# MSS_CTRL_MSS_CTRL_50D00000h register map
Vendor: Texas Instruments
Registers are 32-bit, read-only, reset values left out (the file's numbers can be read two ways) unless marked. A register's access mark holds for its fields unless they carry their own. Offsets are as the file gives them; [hi:lo] are bit positions.

## MSS_CTRL (part 7 of 10)
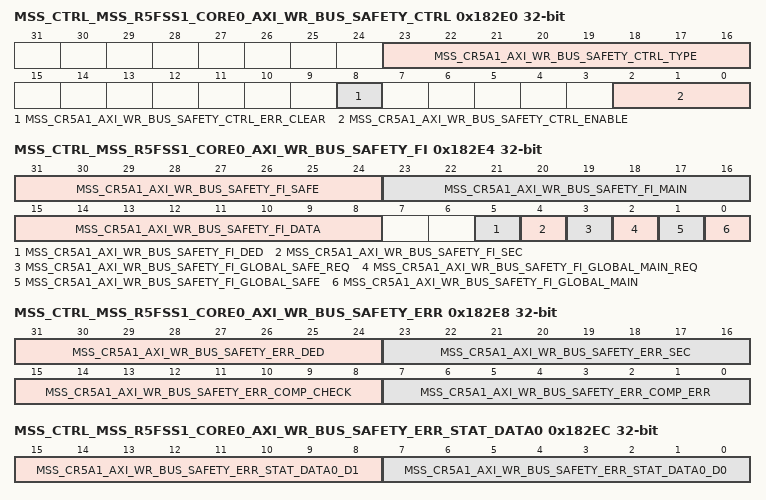
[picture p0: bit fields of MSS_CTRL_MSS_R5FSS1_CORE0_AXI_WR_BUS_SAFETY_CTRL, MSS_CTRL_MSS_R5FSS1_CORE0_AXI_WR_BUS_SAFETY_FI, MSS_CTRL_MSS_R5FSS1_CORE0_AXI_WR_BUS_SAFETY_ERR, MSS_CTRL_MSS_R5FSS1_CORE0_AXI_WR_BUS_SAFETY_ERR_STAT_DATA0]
0x182E0 MSS_CTRL_MSS_R5FSS1_CORE0_AXI_WR_BUS_SAFETY_CTRL access per field — This register is used to Control and Configure the Interconnect Safety Behaviour of R5SS1 CORE0 AXI WR Initiator Port.
  [23:16] MSS_CR5A1_AXI_WR_BUS_SAFETY_CTRL_TYPE ro — This bitfield gives a top level idea of the available bus [cmd,wr,ws,rd] for the particular Target/Initiator and whether it follows the VBUS protocol or not. Bit 0 - 1'b1 indicates the Command bus is implemented to this target/initiator else it is set to 1'b0. Bit 1 - 1'b1 indicates the write bus is implemented to this target/initiator else it is set to 1'b0. Bit 2 - 1'b1 indicates the write status bus is implemented to this target/initiator else it is set to 1'b0. Bit 3 - 1'b1 indicates the read bus is implemented to this target/initiator else it is set to 1'b0. Bit 4 - 1'b0 indicates the port follows the VBUS protocol else it is set to 1'b1. Bits 5-7 are set to 3'b000.
  [8] MSS_CR5A1_AXI_WR_BUS_SAFETY_CTRL_ERR_CLEAR rw — Set this bit to 1'b1 to clear the error status for this port
  [2:0] MSS_CR5A1_AXI_WR_BUS_SAFETY_CTRL_ENABLE rw — Set this bit to 3'b111 to enable the safety configuration for this port. Set this bit to 3'b000 to disable the safety configuration for this port.
0x182E4 MSS_CTRL_MSS_R5FSS1_CORE0_AXI_WR_BUS_SAFETY_FI rw — This register is used to Inject fault on the Interconnect Safety comparator of R5SS1 CORE0 AXI WR Initiator Port.
  [31:24] MSS_CR5A1_AXI_WR_BUS_SAFETY_FI_SAFE — This bitfield is used to inject fault on Read, write, command and request bus on the safe Interconnect. Bit 0 - Set this bit to inject fault on the Command bus. Bit 1 - Set this bit to inject fault on theWrite bus. Bit 2 - Set this bit to inject fault on the Write Status bus.Bit 3 - Set this bit to inject fault on the Read bus. Bit 7- Set this bit to inject fault on the corresponding request bus.
  [23:16] MSS_CR5A1_AXI_WR_BUS_SAFETY_FI_MAIN — This bitfield is used to inject fault on Read, write, command and request bus on the main Interconnect.Bit 0 - Set this bit to inject fault on the Command bus. Bit 1 - Set this bit to inject fault on theWrite bus. Bit 2 - Set this bit to inject fault on the Write Status bus.Bit 3 - Set this bit to inject fault on the Read bus. Bit 7- Set this bit to inject fault on the corresponding request bus.
  [15:8] MSS_CR5A1_AXI_WR_BUS_SAFETY_FI_DATA — Set bit 0 to 1'b1 to inject sec and ded faults on [31:0] bits of data bus.Set bit 1 to 1'b1 to inject sec and ded faults on [64:32] bits of data bus.
  [5] MSS_CR5A1_AXI_WR_BUS_SAFETY_FI_DED — Set this bit to 1'b1 inject ded error on data at this port
  [4] MSS_CR5A1_AXI_WR_BUS_SAFETY_FI_SEC — Set this bit to 1'b1 to inject sec error on data at this port
  [3] MSS_CR5A1_AXI_WR_BUS_SAFETY_FI_GLOBAL_SAFE_REQ — Set this bit 1'b1 to inject fault for request signals on Safe Interconnect. This is enabled only when the 7th bit of safe bitfield of this register and particular bit coressponding to this port on the safe bitfield of this register is set HIGH
  [2] MSS_CR5A1_AXI_WR_BUS_SAFETY_FI_GLOBAL_MAIN_REQ — Set this bit to 1'b1 to inject fault for request signals on main Interconnect. This is enabled only when the 7th bit of main bitfield of this register and particular bit coressponding to this port on the main bitfield of this register is set HIGH
  [1] MSS_CR5A1_AXI_WR_BUS_SAFETY_FI_GLOBAL_SAFE — This is a global safe Fault injection signal. Set this bit to inject fault on all the safety buses of the safe interconnect except req signal. Writing a 1'b1 injects fault on interconnect.
  [0] MSS_CR5A1_AXI_WR_BUS_SAFETY_FI_GLOBAL_MAIN — This is a global main Fault injection signal. Set this bit to inject fault on all the buses of the main interconnect except req signal. Writing a 1'b1 injects fault on interconnect.
0x182E8 MSS_CTRL_MSS_R5FSS1_CORE0_AXI_WR_BUS_SAFETY_ERR — This Register provides the Error Status of Bus Safety Comparator of R5SS1 CORE0 AXI WR Initiator port.
  [31:24] MSS_CR5A1_AXI_WR_BUS_SAFETY_ERR_DED — This flag signals detection of dual error in Data at this port.Flag is generted for 32 bit segment of Data BusBit 0 - 1'b1 indicates ded on [31:0] bit of Data busBit 1 - 1'b1 indicates ded on [63:32] bit of Data busBit [7:2] - Unused. Set to 1'b0
  [23:16] MSS_CR5A1_AXI_WR_BUS_SAFETY_ERR_SEC — This flag signals detection of single error in Data at this port. Flag is generted for 32 bit segment of Data BusBit 0 - 1'b1 indicates sec on [31:0] bit of Data busBit 1 - 1'b1 indicates sec on [63:32] bit of Data busBit [7:2] - Unused. Set to 1'b0
  [15:8] MSS_CR5A1_AXI_WR_BUS_SAFETY_ERR_COMP_CHECK — This is used to verify the proper functioning of fault Injection on all the buses.1'b1 indicates error in the corresponding Bus has been injected successfully. Bit 0 - This is a Bitwise AND of error compares of all command bus signals.Bit 1 - This is a Bitwise AND of error compares of all write bus signals.Bit 2 - This is a Bitwise AND of error compares of all write status bus signals.Bit 3 - This is a Bitwise AND of error compares of all read bus signals.Bits [7:4] are unused.
  [7:0] MSS_CR5A1_AXI_WR_BUS_SAFETY_ERR_COMP_ERR — 1'b1 indicates error in the corresponding Bus whenever a fault is detected at any bus signalBit 0 - This is a Bitwise OR of error compares of all command bus signals.Bit 1 - This is a Bitwise OR of error compares of all write bus signals.Bit 2 - This is a Bitwise OR of error compares of all write status bus signals.Bit 3 - This is a Bitwise OR of error compares of all read bus signals.Bits [7:4] are unused.
0x182EC MSS_CTRL_MSS_R5FSS1_CORE0_AXI_WR_BUS_SAFETY_ERR_STAT_DATA0 — This register Indicates the Error Syndrome of Data errors in Bus Safety Comparator of R5SS1 CORE0 AXI WR Initiator Port.
  [15:8] MSS_CR5A1_AXI_WR_BUS_SAFETY_ERR_STAT_DATA0_D1 — Read this bitfield for Comparator status for Higher 32 bits [63:32] of data bus at this port. It represent the position of the flipped bit in case of SEC.
  [7:0] MSS_CR5A1_AXI_WR_BUS_SAFETY_ERR_STAT_DATA0_D0 — Read this bitfield for Comparator status for lower 32 bits [31:0] of data bus at this port. It represent the position of the flipped bit in case of SEC.
0x182F0 MSS_CTRL_MSS_R5FSS1_CORE0_AXI_WR_BUS_SAFETY_ERR_STAT_CMD — This register Indicates the Error Syndrome of Command errors in Bus Safety Comparator of R5SS1 CORE0 AXI WR Initiator Port.
  [31:0] MSS_CR5A1_AXI_WR_BUS_SAFETY_ERR_STAT_CMD_STAT — Read this bitfield for comparator status for command bus for this port. 1'b1 on any of the bits indicates an error on Command Bus
0x182F4 MSS_CTRL_MSS_R5FSS1_CORE0_AXI_WR_BUS_SAFETY_ERR_STAT_WRITE — This register Indicates the Error Syndrome of Write errors in Bus Safety Comparator of R5SS1 CORE0 AXI WR Initiator Port.
  [31:0] MSS_CR5A1_AXI_WR_BUS_SAFETY_ERR_STAT_WRITE_STAT — Read this bitfield for comparator status for Write bus for this port. 1'b1 at any bit indicates error on Write Bus
0x182F8 MSS_CTRL_MSS_R5FSS1_CORE0_AXI_WR_BUS_SAFETY_ERR_STAT_WRITERESP — This register Indicates the Error Syndrome of Write Response errors in Bus Safety Comparator of R5SS1 CORE0 AXI WR Initiator Port.
  [31:0] MSS_CR5A1_AXI_WR_BUS_SAFETY_ERR_STAT_WRITERESP_STAT — Read this bitfield for comparator status for Write response bus for this port. 1'b1 at any bit indicates error on Write Response Bus.
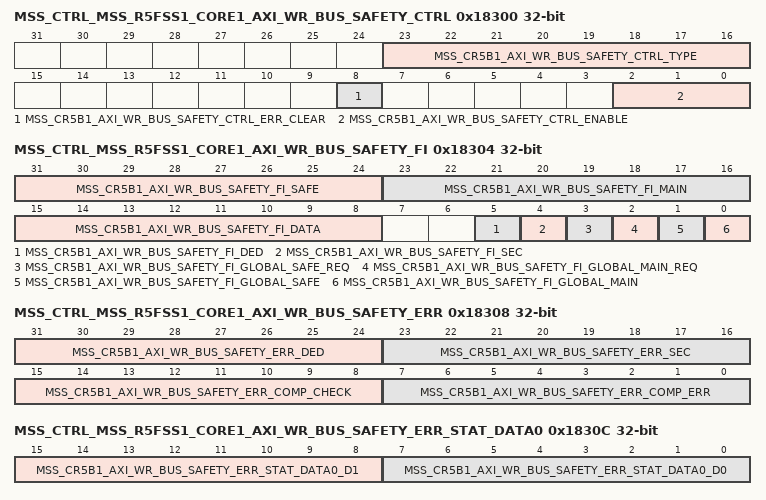
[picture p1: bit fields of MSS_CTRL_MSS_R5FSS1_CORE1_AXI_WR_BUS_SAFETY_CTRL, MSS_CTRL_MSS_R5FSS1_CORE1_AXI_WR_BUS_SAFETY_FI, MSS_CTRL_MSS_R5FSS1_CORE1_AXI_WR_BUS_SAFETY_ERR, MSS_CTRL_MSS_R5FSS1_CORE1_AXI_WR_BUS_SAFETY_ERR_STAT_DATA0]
0x18300 MSS_CTRL_MSS_R5FSS1_CORE1_AXI_WR_BUS_SAFETY_CTRL access per field — This register is used to Control and Configure the Interconnect Safety Behaviour of R5SS1 CORE1 AXI WR Initiator Port.
  [23:16] MSS_CR5B1_AXI_WR_BUS_SAFETY_CTRL_TYPE ro — This bitfield gives a top level idea of the available bus [cmd,wr,ws,rd] for the particular Target/Initiator and whether it follows the VBUS protocol or not. Bit 0 - 1'b1 indicates the Command bus is implemented to this target/initiator else it is set to 1'b0. Bit 1 - 1'b1 indicates the write bus is implemented to this target/initiator else it is set to 1'b0. Bit 2 - 1'b1 indicates the write status bus is implemented to this target/initiator else it is set to 1'b0. Bit 3 - 1'b1 indicates the read bus is implemented to this target/initiator else it is set to 1'b0. Bit 4 - 1'b0 indicates the port follows the VBUS protocol else it is set to 1'b1. Bits 5-7 are set to 3'b000.
  [8] MSS_CR5B1_AXI_WR_BUS_SAFETY_CTRL_ERR_CLEAR rw — Set this bit to 1'b1 to clear the error status for this port
  [2:0] MSS_CR5B1_AXI_WR_BUS_SAFETY_CTRL_ENABLE rw — Set this bit to 3'b111 to enable the safety configuration for this port. Set this bit to 3'b000 to disable the safety configuration for this port.
0x18304 MSS_CTRL_MSS_R5FSS1_CORE1_AXI_WR_BUS_SAFETY_FI rw — This register is used to Inject fault on the Interconnect Safety comparator of R5SS1 CORE1 AXI WR Initiator Port.
  [31:24] MSS_CR5B1_AXI_WR_BUS_SAFETY_FI_SAFE — This bitfield is used to inject fault on Read, write, command and request bus on the safe Interconnect. Bit 0 - Set this bit to inject fault on the Command bus. Bit 1 - Set this bit to inject fault on theWrite bus. Bit 2 - Set this bit to inject fault on the Write Status bus.Bit 3 - Set this bit to inject fault on the Read bus. Bit 7- Set this bit to inject fault on the corresponding request bus.
  [23:16] MSS_CR5B1_AXI_WR_BUS_SAFETY_FI_MAIN — This bitfield is used to inject fault on Read, write, command and request bus on the main Interconnect.Bit 0 - Set this bit to inject fault on the Command bus. Bit 1 - Set this bit to inject fault on theWrite bus. Bit 2 - Set this bit to inject fault on the Write Status bus.Bit 3 - Set this bit to inject fault on the Read bus. Bit 7- Set this bit to inject fault on the corresponding request bus.
  [15:8] MSS_CR5B1_AXI_WR_BUS_SAFETY_FI_DATA — Set bit 0 to 1'b1 to inject sec and ded faults on [31:0] bits of data bus.Set bit 1 to 1'b1 to inject sec and ded faults on [64:32] bits of data bus.
  [5] MSS_CR5B1_AXI_WR_BUS_SAFETY_FI_DED — Set this bit to 1'b1 inject ded error on data at this port
  [4] MSS_CR5B1_AXI_WR_BUS_SAFETY_FI_SEC — Set this bit to 1'b1 to inject sec error on data at this port
  [3] MSS_CR5B1_AXI_WR_BUS_SAFETY_FI_GLOBAL_SAFE_REQ — Set this bit 1'b1 to inject fault for request signals on Safe Interconnect. This is enabled only when the 7th bit of safe bitfield of this register and particular bit coressponding to this port on the safe bitfield of this register is set HIGH
  [2] MSS_CR5B1_AXI_WR_BUS_SAFETY_FI_GLOBAL_MAIN_REQ — Set this bit to 1'b1 to inject fault for request signals on main Interconnect. This is enabled only when the 7th bit of main bitfield of this register and particular bit coressponding to this port on the main bitfield of this register is set HIGH
  [1] MSS_CR5B1_AXI_WR_BUS_SAFETY_FI_GLOBAL_SAFE — This is a global safe Fault injection signal. Set this bit to inject fault on all the safety buses of the safe interconnect except req signal. Writing a 1'b1 injects fault on interconnect.
  [0] MSS_CR5B1_AXI_WR_BUS_SAFETY_FI_GLOBAL_MAIN — This is a global main Fault injection signal. Set this bit to inject fault on all the buses of the main interconnect except req signal. Writing a 1'b1 injects fault on interconnect.
0x18308 MSS_CTRL_MSS_R5FSS1_CORE1_AXI_WR_BUS_SAFETY_ERR — This Register provides the Error Status of Bus Safety Comparator of R5SS1 CORE1 AXI WR Initiator port.
  [31:24] MSS_CR5B1_AXI_WR_BUS_SAFETY_ERR_DED — This flag signals detection of dual error in Data at this port.Flag is generted for 32 bit segment of Data BusBit 0 - 1'b1 indicates ded on [31:0] bit of Data busBit 1 - 1'b1 indicates ded on [63:32] bit of Data busBit [7:2] - Unused. Set to 1'b0
  [23:16] MSS_CR5B1_AXI_WR_BUS_SAFETY_ERR_SEC — This flag signals detection of single error in Data at this port. Flag is generted for 32 bit segment of Data BusBit 0 - 1'b1 indicates sec on [31:0] bit of Data busBit 1 - 1'b1 indicates sec on [63:32] bit of Data busBit [7:2] - Unused. Set to 1'b0
  [15:8] MSS_CR5B1_AXI_WR_BUS_SAFETY_ERR_COMP_CHECK — This is used to verify the proper functioning of fault Injection on all the buses.1'b1 indicates error in the corresponding Bus has been injected successfully. Bit 0 - This is a Bitwise AND of error compares of all command bus signals.Bit 1 - This is a Bitwise AND of error compares of all write bus signals.Bit 2 - This is a Bitwise AND of error compares of all write status bus signals.Bit 3 - This is a Bitwise AND of error compares of all read bus signals.Bits [7:4] are unused.
  [7:0] MSS_CR5B1_AXI_WR_BUS_SAFETY_ERR_COMP_ERR — 1'b1 indicates error in the corresponding Bus whenever a fault is detected at any bus signalBit 0 - This is a Bitwise OR of error compares of all command bus signals.Bit 1 - This is a Bitwise OR of error compares of all write bus signals.Bit 2 - This is a Bitwise OR of error compares of all write status bus signals.Bit 3 - This is a Bitwise OR of error compares of all read bus signals.Bits [7:4] are unused.
0x1830C MSS_CTRL_MSS_R5FSS1_CORE1_AXI_WR_BUS_SAFETY_ERR_STAT_DATA0 — This register Indicates the Error Syndrome of Data errors in Bus Safety Comparator of R5SS1 CORE1 AXI WR Initiator Port.
  [15:8] MSS_CR5B1_AXI_WR_BUS_SAFETY_ERR_STAT_DATA0_D1 — Read this bitfield for Comparator status for Higher 32 bits [63:32] of data bus at this port. It represent the position of the flipped bit in case of SEC.
  [7:0] MSS_CR5B1_AXI_WR_BUS_SAFETY_ERR_STAT_DATA0_D0 — Read this bitfield for Comparator status for lower 32 bits [31:0] of data bus at this port. It represent the position of the flipped bit in case of SEC.
0x18310 MSS_CTRL_MSS_R5FSS1_CORE1_AXI_WR_BUS_SAFETY_ERR_STAT_CMD — This register Indicates the Error Syndrome of Command errors in Bus Safety Comparator of R5SS1 CORE1 AXI WR Initiator Port.
  [31:0] MSS_CR5B1_AXI_WR_BUS_SAFETY_ERR_STAT_CMD_STAT — Read this bitfield for comparator status for command bus for this port. 1'b1 on any of the bits indicates an error on Command Bus
0x18314 MSS_CTRL_MSS_R5FSS1_CORE1_AXI_WR_BUS_SAFETY_ERR_STAT_WRITE — This register Indicates the Error Syndrome of Write errors in Bus Safety Comparator of R5SS1 CORE1 AXI WR Initiator Port.
  [31:0] MSS_CR5B1_AXI_WR_BUS_SAFETY_ERR_STAT_WRITE_STAT — Read this bitfield for comparator status for Write bus for this port. 1'b1 at any bit indicates error on Write Bus
0x18318 MSS_CTRL_MSS_R5FSS1_CORE1_AXI_WR_BUS_SAFETY_ERR_STAT_WRITERESP — This register Indicates the Error Syndrome of Write Response errors in Bus Safety Comparator of R5SS1 CORE1 AXI WR Initiator Port.
  [31:0] MSS_CR5B1_AXI_WR_BUS_SAFETY_ERR_STAT_WRITERESP_STAT — Read this bitfield for comparator status for Write response bus for this port. 1'b1 at any bit indicates error on Write Response Bus.
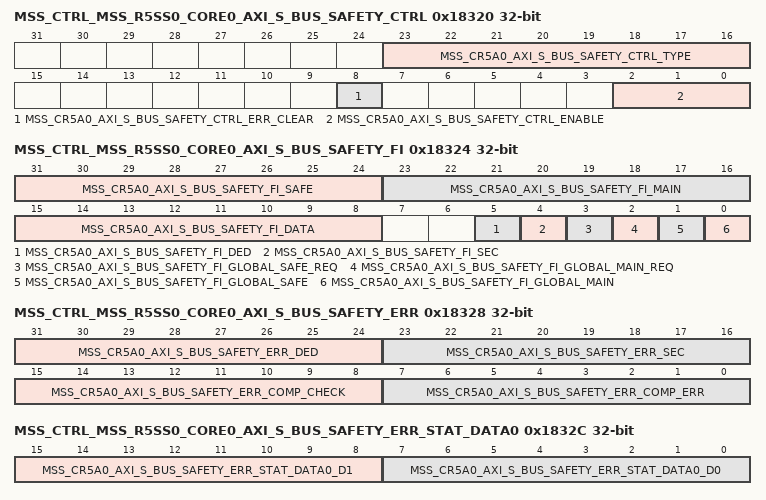
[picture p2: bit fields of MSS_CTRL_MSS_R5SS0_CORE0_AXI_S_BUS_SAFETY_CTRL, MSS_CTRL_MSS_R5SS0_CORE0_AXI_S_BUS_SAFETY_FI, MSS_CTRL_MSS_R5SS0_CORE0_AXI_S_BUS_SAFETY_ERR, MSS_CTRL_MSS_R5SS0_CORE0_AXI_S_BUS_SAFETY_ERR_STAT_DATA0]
0x18320 MSS_CTRL_MSS_R5SS0_CORE0_AXI_S_BUS_SAFETY_CTRL access per field — This register is used to Control and Configure the Interconnect Safety Behaviour of R5SS0 CORE0 AXI Target Port.
  [23:16] MSS_CR5A0_AXI_S_BUS_SAFETY_CTRL_TYPE ro — This bitfield gives a top level idea of the available bus [cmd,wr,ws,rd] for the particular Target/Initiator and whether it follows the VBUS protocol or not. Bit 0 - 1'b1 indicates the Command bus is implemented to this target/initiator else it is set to 1'b0. Bit 1 - 1'b1 indicates the write bus is implemented to this target/initiator else it is set to 1'b0. Bit 2 - 1'b1 indicates the write status bus is implemented to this target/initiator else it is set to 1'b0. Bit 3 - 1'b1 indicates the read bus is implemented to this target/initiator else it is set to 1'b0. Bit 4 - 1'b0 indicates the port follows the VBUS protocol else it is set to 1'b1. Bits 5-7 are set to 3'b000.
  [8] MSS_CR5A0_AXI_S_BUS_SAFETY_CTRL_ERR_CLEAR rw — Set this bit to 1'b1 to clear the error status for this port
  [2:0] MSS_CR5A0_AXI_S_BUS_SAFETY_CTRL_ENABLE rw — Set this bit to 3'b111 to enable the safety configuration for this port. Set this bit to 3'b000 to disable the safety configuration for this port.
0x18324 MSS_CTRL_MSS_R5SS0_CORE0_AXI_S_BUS_SAFETY_FI rw — This register is used to Inject fault on the Interconnect Safety comparator of R5SS0 CORE0 AXI Target Port.
  [31:24] MSS_CR5A0_AXI_S_BUS_SAFETY_FI_SAFE — This bitfield is used to inject fault on Read, write, command and request bus on the safe Interconnect. Bit 0 - Set this bit to inject fault on the Command bus. Bit 1 - Set this bit to inject fault on theWrite bus. Bit 2 - Set this bit to inject fault on the Write Status bus.Bit 3 - Set this bit to inject fault on the Read bus. Bit 7- Set this bit to inject fault on the corresponding request bus.
  [23:16] MSS_CR5A0_AXI_S_BUS_SAFETY_FI_MAIN — This bitfield is used to inject fault on Read, write, command and request bus on the main Interconnect.Bit 0 - Set this bit to inject fault on the Command bus. Bit 1 - Set this bit to inject fault on theWrite bus. Bit 2 - Set this bit to inject fault on the Write Status bus.Bit 3 - Set this bit to inject fault on the Read bus. Bit 7- Set this bit to inject fault on the corresponding request bus.
  [15:8] MSS_CR5A0_AXI_S_BUS_SAFETY_FI_DATA — Set bit 0 to 1'b1 to inject sec and ded faults on [31:0] bits of data bus.Set bit 1 to 1'b1 to inject sec and ded faults on [64:32] bits of data bus.
  [5] MSS_CR5A0_AXI_S_BUS_SAFETY_FI_DED — Set this bit to 1'b1 inject ded error on data at this port
  [4] MSS_CR5A0_AXI_S_BUS_SAFETY_FI_SEC — Set this bit to 1'b1 to inject sec error on data at this port
  [3] MSS_CR5A0_AXI_S_BUS_SAFETY_FI_GLOBAL_SAFE_REQ — Set this bit 1'b1 to inject fault for request signals on Safe Interconnect. This is enabled only when the 7th bit of safe bitfield of this register and particular bit coressponding to this port on the safe bitfield of this register is set HIGH
  [2] MSS_CR5A0_AXI_S_BUS_SAFETY_FI_GLOBAL_MAIN_REQ — Set this bit to 1'b1 to inject fault for request signals on main Interconnect. This is enabled only when the 7th bit of main bitfield of this register and particular bit coressponding to this port on the main bitfield of this register is set HIGH
  [1] MSS_CR5A0_AXI_S_BUS_SAFETY_FI_GLOBAL_SAFE — This is a global safe Fault injection signal. Set this bit to inject fault on all the safety buses of the safe interconnect except req signal. Writing a 1'b1 injects fault on interconnect.
  [0] MSS_CR5A0_AXI_S_BUS_SAFETY_FI_GLOBAL_MAIN — This is a global main Fault injection signal. Set this bit to inject fault on all the buses of the main interconnect except req signal. Writing a 1'b1 injects fault on interconnect.
0x18328 MSS_CTRL_MSS_R5SS0_CORE0_AXI_S_BUS_SAFETY_ERR — This Register provides the Error Status of Bus Safety Comparator of R5SS0 CORE0 AXI Target Port.
  [31:24] MSS_CR5A0_AXI_S_BUS_SAFETY_ERR_DED — This flag signals detection of dual error in Data at this port.Flag is generted for 32 bit segment of Data BusBit 0 - 1'b1 indicates ded on [31:0] bit of Data busBit 1 - 1'b1 indicates ded on [63:32] bit of Data busBit [7:2] - Unused. Set to 1'b0
  [23:16] MSS_CR5A0_AXI_S_BUS_SAFETY_ERR_SEC — This flag signals detection of single error in Data at this port. Flag is generted for 32 bit segment of Data BusBit 0 - 1'b1 indicates sec on [31:0] bit of Data busBit 1 - 1'b1 indicates sec on [63:32] bit of Data busBit [7:2] - Unused. Set to 1'b0
  [15:8] MSS_CR5A0_AXI_S_BUS_SAFETY_ERR_COMP_CHECK — This is used to verify the proper functioning of fault Injection on all the buses.1'b1 indicates error in the corresponding Bus has been injected successfully. Bit 0 - This is a Bitwise AND of error compares of all command bus signals.Bit 1 - This is a Bitwise AND of error compares of all write bus signals.Bit 2 - This is a Bitwise AND of error compares of all write status bus signals.Bit 3 - This is a Bitwise AND of error compares of all read bus signals.Bits [7:4] are unused.
  [7:0] MSS_CR5A0_AXI_S_BUS_SAFETY_ERR_COMP_ERR — 1'b1 indicates error in the corresponding Bus whenever a fault is detected at any bus signalBit 0 - This is a Bitwise OR of error compares of all command bus signals.Bit 1 - This is a Bitwise OR of error compares of all write bus signals.Bit 2 - This is a Bitwise OR of error compares of all write status bus signals.Bit 3 - This is a Bitwise OR of error compares of all read bus signals.Bits [7:4] are unused.
0x1832C MSS_CTRL_MSS_R5SS0_CORE0_AXI_S_BUS_SAFETY_ERR_STAT_DATA0 — This register Indicates the Error Syndrome of Data errors in Bus Safety Comparator of R5SS0 CORE0 AXI Target Port.
  [15:8] MSS_CR5A0_AXI_S_BUS_SAFETY_ERR_STAT_DATA0_D1 — Read this bitfield for Comparator status for Higher 32 bits [63:32] of data bus at this port. It represent the position of the flipped bit in case of SEC.
  [7:0] MSS_CR5A0_AXI_S_BUS_SAFETY_ERR_STAT_DATA0_D0 — Read this bitfield for Comparator status for lower 32 bits [31:0] of data bus at this port. It represent the position of the flipped bit in case of SEC.
0x18330 MSS_CTRL_MSS_R5SS0_CORE0_AXI_S_BUS_SAFETY_ERR_STAT_CMD — This register Indicates the Error Syndrome of Command errors in Bus Safety Comparator of R5SS0 CORE0 AXI Target Port.
  [31:0] MSS_CR5A0_AXI_S_BUS_SAFETY_ERR_STAT_CMD_STAT — Read this bitfield for comparator status for command bus for this port. 1'b1 on any of the bits indicates an error on Command Bus
0x18334 MSS_CTRL_MSS_R5SS0_CORE0_AXI_S_BUS_SAFETY_ERR_STAT_WRITE — This register Indicates the Error Syndrome of Write errors in Bus Safety Comparator of R5SS0 CORE0 AXI Target Port.
  [31:0] MSS_CR5A0_AXI_S_BUS_SAFETY_ERR_STAT_WRITE_STAT — Read this bitfield for comparator status for Write bus for this port. 1'b1 at any bit indicates error on Write Bus
0x18338 MSS_CTRL_MSS_R5SS0_CORE0_AXI_S_BUS_SAFETY_ERR_STAT_READ — This register Indicates the Error Syndrome of Read errors in Bus Safety Comparator of R5SS0 CORE0 AXI Target Port.
  [31:0] MSS_CR5A0_AXI_S_BUS_SAFETY_ERR_STAT_READ_STAT — Read this bitfield for comapartor status for read signals at this port. 1'b1 on any of the bits indicates an error on Read bus.
0x1833C MSS_CTRL_MSS_R5SS0_CORE0_AXI_S_BUS_SAFETY_ERR_STAT_WRITERESP — This register Indicates the Error Syndrome of WriteResponse errors in Bus Safety Comparator of R5SS0 CORE0 AXI Target Port.
  [31:0] MSS_CR5A0_AXI_S_BUS_SAFETY_ERR_STAT_WRITERESP_STAT — Read this bitfield for comparator status for Write response bus for this port. 1'b1 at any bit indicates error on Write Response Bus.
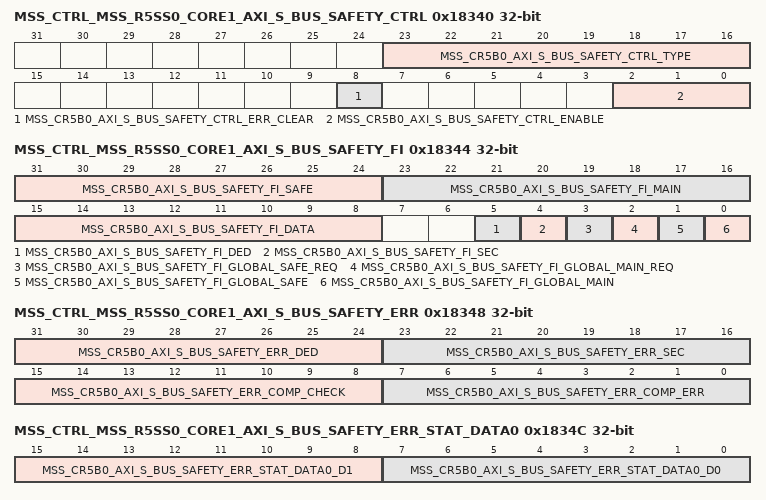
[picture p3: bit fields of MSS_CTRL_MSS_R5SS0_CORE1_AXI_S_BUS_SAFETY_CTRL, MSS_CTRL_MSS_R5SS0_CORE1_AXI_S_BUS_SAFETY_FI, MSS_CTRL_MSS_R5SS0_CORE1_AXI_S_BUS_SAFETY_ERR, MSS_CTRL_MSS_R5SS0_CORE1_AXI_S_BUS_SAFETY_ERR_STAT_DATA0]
0x18340 MSS_CTRL_MSS_R5SS0_CORE1_AXI_S_BUS_SAFETY_CTRL access per field — This register is used to Control and Configure the Interconnect Safety Behaviour of R5SS0 CORE1 AXI Target Port.
  [23:16] MSS_CR5B0_AXI_S_BUS_SAFETY_CTRL_TYPE ro — This bitfield gives a top level idea of the available bus [cmd,wr,ws,rd] for the particular Target/Initiator and whether it follows the VBUS protocol or not. Bit 0 - 1'b1 indicates the Command bus is implemented to this target/initiator else it is set to 1'b0. Bit 1 - 1'b1 indicates the write bus is implemented to this target/initiator else it is set to 1'b0. Bit 2 - 1'b1 indicates the write status bus is implemented to this target/initiator else it is set to 1'b0. Bit 3 - 1'b1 indicates the read bus is implemented to this target/initiator else it is set to 1'b0. Bit 4 - 1'b0 indicates the port follows the VBUS protocol else it is set to 1'b1. Bits 5-7 are set to 3'b000.
  [8] MSS_CR5B0_AXI_S_BUS_SAFETY_CTRL_ERR_CLEAR rw — Set this bit to 1'b1 to clear the error status for this port
  [2:0] MSS_CR5B0_AXI_S_BUS_SAFETY_CTRL_ENABLE rw — Set this bit to 3'b111 to enable the safety configuration for this port. Set this bit to 3'b000 to disable the safety configuration for this port.
0x18344 MSS_CTRL_MSS_R5SS0_CORE1_AXI_S_BUS_SAFETY_FI rw — This register is used to Inject fault on the Interconnect Safety comparator of R5SS0 CORE1 AXI Target Port.
  [31:24] MSS_CR5B0_AXI_S_BUS_SAFETY_FI_SAFE — This bitfield is used to inject fault on Read, write, command and request bus on the safe Interconnect. Bit 0 - Set this bit to inject fault on the Command bus. Bit 1 - Set this bit to inject fault on theWrite bus. Bit 2 - Set this bit to inject fault on the Write Status bus.Bit 3 - Set this bit to inject fault on the Read bus. Bit 7- Set this bit to inject fault on the corresponding request bus.
  [23:16] MSS_CR5B0_AXI_S_BUS_SAFETY_FI_MAIN — This bitfield is used to inject fault on Read, write, command and request bus on the main Interconnect.Bit 0 - Set this bit to inject fault on the Command bus. Bit 1 - Set this bit to inject fault on theWrite bus. Bit 2 - Set this bit to inject fault on the Write Status bus.Bit 3 - Set this bit to inject fault on the Read bus. Bit 7- Set this bit to inject fault on the corresponding request bus.
  [15:8] MSS_CR5B0_AXI_S_BUS_SAFETY_FI_DATA — Set bit 0 to 1'b1 to inject sec and ded faults on [31:0] bits of data bus.Set bit 1 to 1'b1 to inject sec and ded faults on [64:32] bits of data bus.
  [5] MSS_CR5B0_AXI_S_BUS_SAFETY_FI_DED — Set this bit to 1'b1 inject ded error on data at this port
  [4] MSS_CR5B0_AXI_S_BUS_SAFETY_FI_SEC — Set this bit to 1'b1 to inject sec error on data at this port
  [3] MSS_CR5B0_AXI_S_BUS_SAFETY_FI_GLOBAL_SAFE_REQ — Set this bit 1'b1 to inject fault for request signals on Safe Interconnect. This is enabled only when the 7th bit of safe bitfield of this register and particular bit coressponding to this port on the safe bitfield of this register is set HIGH
  [2] MSS_CR5B0_AXI_S_BUS_SAFETY_FI_GLOBAL_MAIN_REQ — Set this bit to 1'b1 to inject fault for request signals on main Interconnect. This is enabled only when the 7th bit of main bitfield of this register and particular bit coressponding to this port on the main bitfield of this register is set HIGH
  [1] MSS_CR5B0_AXI_S_BUS_SAFETY_FI_GLOBAL_SAFE — This is a global safe Fault injection signal. Set this bit to inject fault on all the safety buses of the safe interconnect except req signal. Writing a 1'b1 injects fault on interconnect.
  [0] MSS_CR5B0_AXI_S_BUS_SAFETY_FI_GLOBAL_MAIN — This is a global main Fault injection signal. Set this bit to inject fault on all the buses of the main interconnect except req signal. Writing a 1'b1 injects fault on interconnect.
0x18348 MSS_CTRL_MSS_R5SS0_CORE1_AXI_S_BUS_SAFETY_ERR — This Register provides the Error Status of Bus Safety Comparator of R5SS0 CORE1 AXI Target Port.
  [31:24] MSS_CR5B0_AXI_S_BUS_SAFETY_ERR_DED — This flag signals detection of dual error in Data at this port.Flag is generted for 32 bit segment of Data BusBit 0 - 1'b1 indicates ded on [31:0] bit of Data busBit 1 - 1'b1 indicates ded on [63:32] bit of Data busBit [7:2] - Unused. Set to 1'b0
  [23:16] MSS_CR5B0_AXI_S_BUS_SAFETY_ERR_SEC — This flag signals detection of single error in Data at this port. Flag is generted for 32 bit segment of Data BusBit 0 - 1'b1 indicates sec on [31:0] bit of Data busBit 1 - 1'b1 indicates sec on [63:32] bit of Data busBit [7:2] - Unused. Set to 1'b0
  [15:8] MSS_CR5B0_AXI_S_BUS_SAFETY_ERR_COMP_CHECK — This is used to verify the proper functioning of fault Injection on all the buses.1'b1 indicates error in the corresponding Bus has been injected successfully. Bit 0 - This is a Bitwise AND of error compares of all command bus signals.Bit 1 - This is a Bitwise AND of error compares of all write bus signals.Bit 2 - This is a Bitwise AND of error compares of all write status bus signals.Bit 3 - This is a Bitwise AND of error compares of all read bus signals.Bits [7:4] are unused.
  [7:0] MSS_CR5B0_AXI_S_BUS_SAFETY_ERR_COMP_ERR — 1'b1 indicates error in the corresponding Bus whenever a fault is detected at any bus signalBit 0 - This is a Bitwise OR of error compares of all command bus signals.Bit 1 - This is a Bitwise OR of error compares of all write bus signals.Bit 2 - This is a Bitwise OR of error compares of all write status bus signals.Bit 3 - This is a Bitwise OR of error compares of all read bus signals.Bits [7:4] are unused.
0x1834C MSS_CTRL_MSS_R5SS0_CORE1_AXI_S_BUS_SAFETY_ERR_STAT_DATA0 — This register Indicates the Error Syndrome of Data errors in Bus Safety Comparator of R5SS0 CORE1 AXI Target Port.
  [15:8] MSS_CR5B0_AXI_S_BUS_SAFETY_ERR_STAT_DATA0_D1 — Read this bitfield for Comparator status for Higher 32 bits [63:32] of data bus at this port. It represent the position of the flipped bit in case of SEC.
  [7:0] MSS_CR5B0_AXI_S_BUS_SAFETY_ERR_STAT_DATA0_D0 — Read this bitfield for Comparator status for lower 32 bits [31:0] of data bus at this port. It represent the position of the flipped bit in case of SEC.
0x18350 MSS_CTRL_MSS_R5SS0_CORE1_AXI_S_BUS_SAFETY_ERR_STAT_CMD — This register Indicates the Error Syndrome of Command errors in Bus Safety Comparator of R5SS0 CORE1 AXI Target Port.
  [31:0] MSS_CR5B0_AXI_S_BUS_SAFETY_ERR_STAT_CMD_STAT — Read this bitfield for comparator status for command bus for this port. 1'b1 on any of the bits indicates an error on Command Bus
0x18354 MSS_CTRL_MSS_R5SS0_CORE1_AXI_S_BUS_SAFETY_ERR_STAT_WRITE — This register Indicates the Error Syndrome of Write errors in Bus Safety Comparator of R5SS0 CORE1 AXI Target Port.
  [31:0] MSS_CR5B0_AXI_S_BUS_SAFETY_ERR_STAT_WRITE_STAT — Read this bitfield for comparator status for Write bus for this port. 1'b1 at any bit indicates error on Write Bus
0x18358 MSS_CTRL_MSS_R5SS0_CORE1_AXI_S_BUS_SAFETY_ERR_STAT_READ — This register Indicates the Error Syndrome of Read errors in Bus Safety Comparator of R5SS0 CORE1 AXI Target Port.
  [31:0] MSS_CR5B0_AXI_S_BUS_SAFETY_ERR_STAT_READ_STAT — Read this bitfield for comapartor status for read signals at this port. 1'b1 on any of the bits indicates an error on Read bus.
0x1835C MSS_CTRL_MSS_R5SS0_CORE1_AXI_S_BUS_SAFETY_ERR_STAT_WRITERESP — This register Indicates the Error Syndrome of WriteResponse errors in Bus Safety Comparator of R5SS0 CORE1 AXI Target Port.
  [31:0] MSS_CR5B0_AXI_S_BUS_SAFETY_ERR_STAT_WRITERESP_STAT — Read this bitfield for comparator status for Write response bus for this port. 1'b1 at any bit indicates error on Write Response Bus.
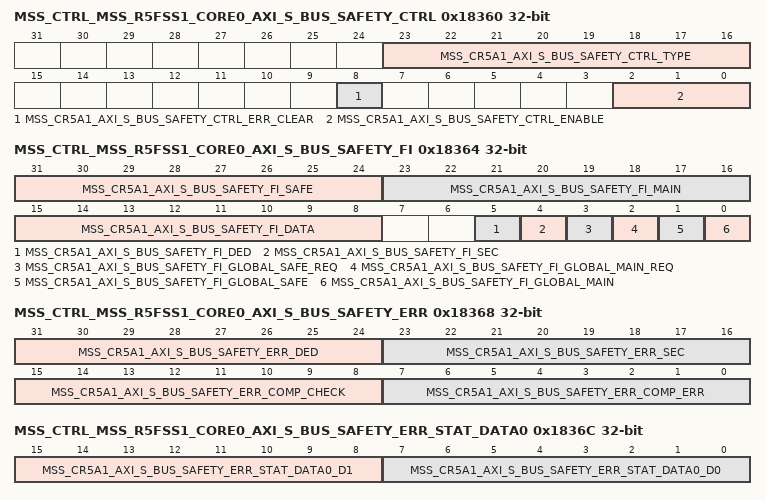
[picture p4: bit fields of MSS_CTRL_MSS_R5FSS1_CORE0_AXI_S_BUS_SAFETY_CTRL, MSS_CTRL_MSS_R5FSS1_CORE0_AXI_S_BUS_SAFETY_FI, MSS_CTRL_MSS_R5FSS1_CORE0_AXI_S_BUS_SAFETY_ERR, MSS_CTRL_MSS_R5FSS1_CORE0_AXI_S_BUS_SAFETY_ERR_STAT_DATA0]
0x18360 MSS_CTRL_MSS_R5FSS1_CORE0_AXI_S_BUS_SAFETY_CTRL access per field — This register is used to Control and Configure the Interconnect Safety Behaviour of R5SS1 CORE0 AXI Target Port.
  [23:16] MSS_CR5A1_AXI_S_BUS_SAFETY_CTRL_TYPE ro — This bitfield gives a top level idea of the available bus [cmd,wr,ws,rd] for the particular Target/Initiator and whether it follows the VBUS protocol or not. Bit 0 - 1'b1 indicates the Command bus is implemented to this target/initiator else it is set to 1'b0. Bit 1 - 1'b1 indicates the write bus is implemented to this target/initiator else it is set to 1'b0. Bit 2 - 1'b1 indicates the write status bus is implemented to this target/initiator else it is set to 1'b0. Bit 3 - 1'b1 indicates the read bus is implemented to this target/initiator else it is set to 1'b0. Bit 4 - 1'b0 indicates the port follows the VBUS protocol else it is set to 1'b1. Bits 5-7 are set to 3'b000.
  [8] MSS_CR5A1_AXI_S_BUS_SAFETY_CTRL_ERR_CLEAR rw — Set this bit to 1'b1 to clear the error status for this port
  [2:0] MSS_CR5A1_AXI_S_BUS_SAFETY_CTRL_ENABLE rw — Set this bit to 3'b111 to enable the safety configuration for this port. Set this bit to 3'b000 to disable the safety configuration for this port.
0x18364 MSS_CTRL_MSS_R5FSS1_CORE0_AXI_S_BUS_SAFETY_FI rw — This register is used to Inject fault on the Interconnect Safety comparator of R5SS1 CORE0 AXI Target Port.
  [31:24] MSS_CR5A1_AXI_S_BUS_SAFETY_FI_SAFE — This bitfield is used to inject fault on Read, write, command and request bus on the safe Interconnect. Bit 0 - Set this bit to inject fault on the Command bus. Bit 1 - Set this bit to inject fault on theWrite bus. Bit 2 - Set this bit to inject fault on the Write Status bus.Bit 3 - Set this bit to inject fault on the Read bus. Bit 7- Set this bit to inject fault on the corresponding request bus.
  [23:16] MSS_CR5A1_AXI_S_BUS_SAFETY_FI_MAIN — This bitfield is used to inject fault on Read, write, command and request bus on the main Interconnect.Bit 0 - Set this bit to inject fault on the Command bus. Bit 1 - Set this bit to inject fault on theWrite bus. Bit 2 - Set this bit to inject fault on the Write Status bus.Bit 3 - Set this bit to inject fault on the Read bus. Bit 7- Set this bit to inject fault on the corresponding request bus.
  [15:8] MSS_CR5A1_AXI_S_BUS_SAFETY_FI_DATA — Set bit 0 to 1'b1 to inject sec and ded faults on [31:0] bits of data bus.Set bit 1 to 1'b1 to inject sec and ded faults on [64:32] bits of data bus.
  [5] MSS_CR5A1_AXI_S_BUS_SAFETY_FI_DED — Set this bit to 1'b1 inject ded error on data at this port
  [4] MSS_CR5A1_AXI_S_BUS_SAFETY_FI_SEC — Set this bit to 1'b1 to inject sec error on data at this port
  [3] MSS_CR5A1_AXI_S_BUS_SAFETY_FI_GLOBAL_SAFE_REQ — Set this bit 1'b1 to inject fault for request signals on Safe Interconnect. This is enabled only when the 7th bit of safe bitfield of this register and particular bit coressponding to this port on the safe bitfield of this register is set HIGH
  [2] MSS_CR5A1_AXI_S_BUS_SAFETY_FI_GLOBAL_MAIN_REQ — Set this bit to 1'b1 to inject fault for request signals on main Interconnect. This is enabled only when the 7th bit of main bitfield of this register and particular bit coressponding to this port on the main bitfield of this register is set HIGH
  [1] MSS_CR5A1_AXI_S_BUS_SAFETY_FI_GLOBAL_SAFE — This is a global safe Fault injection signal. Set this bit to inject fault on all the safety buses of the safe interconnect except req signal. Writing a 1'b1 injects fault on interconnect.
  [0] MSS_CR5A1_AXI_S_BUS_SAFETY_FI_GLOBAL_MAIN — This is a global main Fault injection signal. Set this bit to inject fault on all the buses of the main interconnect except req signal. Writing a 1'b1 injects fault on interconnect.
0x18368 MSS_CTRL_MSS_R5FSS1_CORE0_AXI_S_BUS_SAFETY_ERR — This Register provides the Error Status of Bus Safety Comparator of R5SS1 CORE0 AXI Target Port.
  [31:24] MSS_CR5A1_AXI_S_BUS_SAFETY_ERR_DED — This flag signals detection of dual error in Data at this port.Flag is generted for 32 bit segment of Data BusBit 0 - 1'b1 indicates ded on [31:0] bit of Data busBit 1 - 1'b1 indicates ded on [63:32] bit of Data busBit [7:2] - Unused. Set to 1'b0
  [23:16] MSS_CR5A1_AXI_S_BUS_SAFETY_ERR_SEC — This flag signals detection of single error in Data at this port. Flag is generted for 32 bit segment of Data BusBit 0 - 1'b1 indicates sec on [31:0] bit of Data busBit 1 - 1'b1 indicates sec on [63:32] bit of Data busBit [7:2] - Unused. Set to 1'b0
  [15:8] MSS_CR5A1_AXI_S_BUS_SAFETY_ERR_COMP_CHECK — This is used to verify the proper functioning of fault Injection on all the buses.1'b1 indicates error in the corresponding Bus has been injected successfully. Bit 0 - This is a Bitwise AND of error compares of all command bus signals.Bit 1 - This is a Bitwise AND of error compares of all write bus signals.Bit 2 - This is a Bitwise AND of error compares of all write status bus signals.Bit 3 - This is a Bitwise AND of error compares of all read bus signals.Bits [7:4] are unused.
  [7:0] MSS_CR5A1_AXI_S_BUS_SAFETY_ERR_COMP_ERR — 1'b1 indicates error in the corresponding Bus whenever a fault is detected at any bus signalBit 0 - This is a Bitwise OR of error compares of all command bus signals.Bit 1 - This is a Bitwise OR of error compares of all write bus signals.Bit 2 - This is a Bitwise OR of error compares of all write status bus signals.Bit 3 - This is a Bitwise OR of error compares of all read bus signals.Bits [7:4] are unused.
0x1836C MSS_CTRL_MSS_R5FSS1_CORE0_AXI_S_BUS_SAFETY_ERR_STAT_DATA0 — This register Indicates the Error Syndrome of Data errors in Bus Safety Comparator of R5SS1 CORE0 AXI Target Port.
  [15:8] MSS_CR5A1_AXI_S_BUS_SAFETY_ERR_STAT_DATA0_D1 — Read this bitfield for Comparator status for Higher 32 bits [63:32] of data bus at this port. It represent the position of the flipped bit in case of SEC.
  [7:0] MSS_CR5A1_AXI_S_BUS_SAFETY_ERR_STAT_DATA0_D0 — Read this bitfield for Comparator status for lower 32 bits [31:0] of data bus at this port. It represent the position of the flipped bit in case of SEC.
0x18370 MSS_CTRL_MSS_R5FSS1_CORE0_AXI_S_BUS_SAFETY_ERR_STAT_CMD — This register Indicates the Error Syndrome of Command errors in Bus Safety Comparator of R5SS1 CORE0 AXI Target Port.
  [31:0] MSS_CR5A1_AXI_S_BUS_SAFETY_ERR_STAT_CMD_STAT — Read this bitfield for comparator status for command bus for this port. 1'b1 on any of the bits indicates an error on Command Bus
0x18374 MSS_CTRL_MSS_R5FSS1_CORE0_AXI_S_BUS_SAFETY_ERR_STAT_WRITE — This register Indicates the Error Syndrome of Write errors in Bus Safety Comparator of R5SS1 CORE0 AXI Target Port.
  [31:0] MSS_CR5A1_AXI_S_BUS_SAFETY_ERR_STAT_WRITE_STAT — Read this bitfield for comparator status for Write bus for this port. 1'b1 at any bit indicates error on Write Bus
0x18378 MSS_CTRL_MSS_R5FSS1_CORE0_AXI_S_BUS_SAFETY_ERR_STAT_READ — This register Indicates the Error Syndrome of Read errors in Bus Safety Comparator of R5SS1 CORE0 AXI Target Port.
  [31:0] MSS_CR5A1_AXI_S_BUS_SAFETY_ERR_STAT_READ_STAT — Read this bitfield for comapartor status for read signals at this port. 1'b1 on any of the bits indicates an error on Read bus.
0x1837C MSS_CTRL_MSS_R5FSS1_CORE0_AXI_S_BUS_SAFETY_ERR_STAT_WRITERESP — This register Indicates the Error Syndrome of WriteResponse errors in Bus Safety Comparator of R5SS1 CORE0 AXI Target Port.
  [31:0] MSS_CR5A1_AXI_S_BUS_SAFETY_ERR_STAT_WRITERESP_STAT — Read this bitfield for comparator status for Write response bus for this port. 1'b1 at any bit indicates error on Write Response Bus.
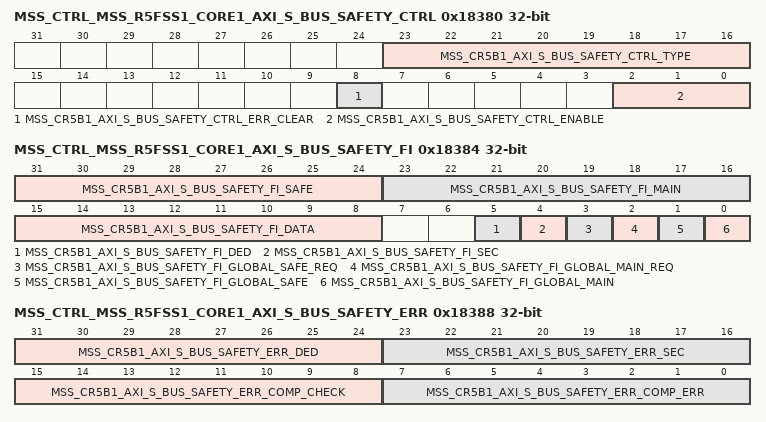
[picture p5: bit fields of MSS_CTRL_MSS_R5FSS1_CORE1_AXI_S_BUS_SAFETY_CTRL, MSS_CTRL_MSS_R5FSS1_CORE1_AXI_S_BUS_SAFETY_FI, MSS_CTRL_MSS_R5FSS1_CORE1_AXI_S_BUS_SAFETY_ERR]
0x18380 MSS_CTRL_MSS_R5FSS1_CORE1_AXI_S_BUS_SAFETY_CTRL access per field — This register is used to Control and Configure the Interconnect Safety Behaviour of R5SS1 CORE1 AXI Target Port.
  [23:16] MSS_CR5B1_AXI_S_BUS_SAFETY_CTRL_TYPE ro — This bitfield gives a top level idea of the available bus [cmd,wr,ws,rd] for the particular Target/Initiator and whether it follows the VBUS protocol or not. Bit 0 - 1'b1 indicates the Command bus is implemented to this target/initiator else it is set to 1'b0. Bit 1 - 1'b1 indicates the write bus is implemented to this target/initiator else it is set to 1'b0. Bit 2 - 1'b1 indicates the write status bus is implemented to this target/initiator else it is set to 1'b0. Bit 3 - 1'b1 indicates the read bus is implemented to this target/initiator else it is set to 1'b0. Bit 4 - 1'b0 indicates the port follows the VBUS protocol else it is set to 1'b1. Bits 5-7 are set to 3'b000.
  [8] MSS_CR5B1_AXI_S_BUS_SAFETY_CTRL_ERR_CLEAR rw — Set this bit to 1'b1 to clear the error status for this port
  [2:0] MSS_CR5B1_AXI_S_BUS_SAFETY_CTRL_ENABLE rw — Set this bit to 3'b111 to enable the safety configuration for this port. Set this bit to 3'b000 to disable the safety configuration for this port.
0x18384 MSS_CTRL_MSS_R5FSS1_CORE1_AXI_S_BUS_SAFETY_FI rw — This register is used to Inject fault on the Interconnect Safety comparator of R5SS1 CORE1 AXI Target Port.
  [31:24] MSS_CR5B1_AXI_S_BUS_SAFETY_FI_SAFE — This bitfield is used to inject fault on Read, write, command and request bus on the safe Interconnect. Bit 0 - Set this bit to inject fault on the Command bus. Bit 1 - Set this bit to inject fault on theWrite bus. Bit 2 - Set this bit to inject fault on the Write Status bus.Bit 3 - Set this bit to inject fault on the Read bus. Bit 7- Set this bit to inject fault on the corresponding request bus.
  [23:16] MSS_CR5B1_AXI_S_BUS_SAFETY_FI_MAIN — This bitfield is used to inject fault on Read, write, command and request bus on the main Interconnect.Bit 0 - Set this bit to inject fault on the Command bus. Bit 1 - Set this bit to inject fault on theWrite bus. Bit 2 - Set this bit to inject fault on the Write Status bus.Bit 3 - Set this bit to inject fault on the Read bus. Bit 7- Set this bit to inject fault on the corresponding request bus.
  [15:8] MSS_CR5B1_AXI_S_BUS_SAFETY_FI_DATA — Set bit 0 to 1'b1 to inject sec and ded faults on [31:0] bits of data bus.Set bit 1 to 1'b1 to inject sec and ded faults on [64:32] bits of data bus.
  [5] MSS_CR5B1_AXI_S_BUS_SAFETY_FI_DED — Set this bit to 1'b1 inject ded error on data at this port
  [4] MSS_CR5B1_AXI_S_BUS_SAFETY_FI_SEC — Set this bit to 1'b1 to inject sec error on data at this port
  [3] MSS_CR5B1_AXI_S_BUS_SAFETY_FI_GLOBAL_SAFE_REQ — Set this bit 1'b1 to inject fault for request signals on Safe Interconnect. This is enabled only when the 7th bit of safe bitfield of this register and particular bit coressponding to this port on the safe bitfield of this register is set HIGH
  [2] MSS_CR5B1_AXI_S_BUS_SAFETY_FI_GLOBAL_MAIN_REQ — Set this bit to 1'b1 to inject fault for request signals on main Interconnect. This is enabled only when the 7th bit of main bitfield of this register and particular bit coressponding to this port on the main bitfield of this register is set HIGH
  [1] MSS_CR5B1_AXI_S_BUS_SAFETY_FI_GLOBAL_SAFE — This is a global safe Fault injection signal. Set this bit to inject fault on all the safety buses of the safe interconnect except req signal. Writing a 1'b1 injects fault on interconnect.
  [0] MSS_CR5B1_AXI_S_BUS_SAFETY_FI_GLOBAL_MAIN — This is a global main Fault injection signal. Set this bit to inject fault on all the buses of the main interconnect except req signal. Writing a 1'b1 injects fault on interconnect.
0x18388 MSS_CTRL_MSS_R5FSS1_CORE1_AXI_S_BUS_SAFETY_ERR — This Register provides the Error Status of Bus Safety Comparator of R5SS1 CORE1 AXI Target Port.
  [31:24] MSS_CR5B1_AXI_S_BUS_SAFETY_ERR_DED — This flag signals detection of dual error in Data at this port.Flag is generted for 32 bit segment of Data BusBit 0 - 1'b1 indicates ded on [31:0] bit of Data busBit 1 - 1'b1 indicates ded on [63:32] bit of Data busBit [7:2] - Unused. Set to 1'b0
  [23:16] MSS_CR5B1_AXI_S_BUS_SAFETY_ERR_SEC — This flag signals detection of single error in Data at this port. Flag is generted for 32 bit segment of Data BusBit 0 - 1'b1 indicates sec on [31:0] bit of Data busBit 1 - 1'b1 indicates sec on [63:32] bit of Data busBit [7:2] - Unused. Set to 1'b0
  [15:8] MSS_CR5B1_AXI_S_BUS_SAFETY_ERR_COMP_CHECK — This is used to verify the proper functioning of fault Injection on all the buses.1'b1 indicates error in the corresponding Bus has been injected successfully. Bit 0 - This is a Bitwise AND of error compares of all command bus signals.Bit 1 - This is a Bitwise AND of error compares of all write bus signals.Bit 2 - This is a Bitwise AND of error compares of all write status bus signals.Bit 3 - This is a Bitwise AND of error compares of all read bus signals.Bits [7:4] are unused.
  [7:0] MSS_CR5B1_AXI_S_BUS_SAFETY_ERR_COMP_ERR — 1'b1 indicates error in the corresponding Bus whenever a fault is detected at any bus signalBit 0 - This is a Bitwise OR of error compares of all command bus signals.Bit 1 - This is a Bitwise OR of error compares of all write bus signals.Bit 2 - This is a Bitwise OR of error compares of all write status bus signals.Bit 3 - This is a Bitwise OR of error compares of all read bus signals.Bits [7:4] are unused.
